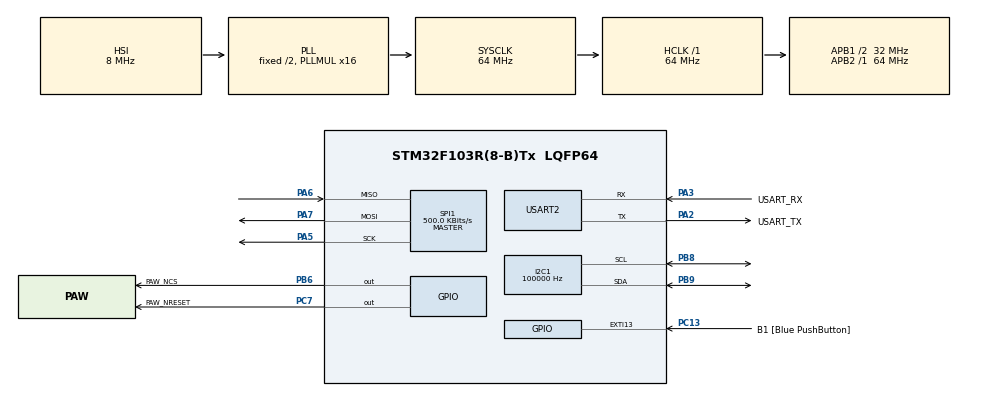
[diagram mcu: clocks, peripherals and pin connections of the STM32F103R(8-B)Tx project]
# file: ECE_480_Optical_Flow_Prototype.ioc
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Mcu.Family=STM32F1
Mcu.Name=STM32F103R(8-B)Tx
Mcu.Package=LQFP64
NVIC.EXTI15_10_IRQn=true\:0\:0\:false\:false\:true\:true\:true\:true
NVIC.PriorityGroup=NVIC_PRIORITYGROUP_4
NVIC.USART2_IRQn=true\:1\:0\:false\:false\:true\:true\:true\:true
PA13.GPIO_Label=TMS
PA13.Mode=Serial_Wire
PA13.Signal=SYS_JTMS-SWDIO
PA14.GPIO_Label=TCK
PA14.Mode=Serial_Wire
PA14.Signal=SYS_JTCK-SWCLK
PA2.GPIO_Label=USART_TX
PA2.GPIO_Mode=GPIO_MODE_AF_PP
PA2.GPIO_PuPd=GPIO_NOPULL
PA2.GPIO_Speed=GPIO_SPEED_FREQ_LOW
PA2.Mode=Asynchronous
PA2.Signal=USART2_TX
PA3.GPIO_Label=USART_RX
PA3.GPIO_Mode=GPIO_MODE_INPUT
PA3.GPIO_PuPd=GPIO_NOPULL
PA3.GPIO_Speed=GPIO_SPEED_FREQ_LOW
PA3.Mode=Asynchronous
PA3.Signal=USART2_RX
PA5.Mode=Full_Duplex_Master
PA5.Signal=SPI1_SCK
PB3.GPIO_Label=SWO
PB3.Signal=SYS_JTDO-TRACESWO
PC13-TAMPER-RTC.GPIO_Label=B1 [Blue PushButton]
PC13-TAMPER-RTC.GPIO_PuPd=GPIO_NOPULL
PC13-TAMPER-RTC.Signal=GPXTI13
PC14-OSC32_IN.Mode=LSE-External-Oscillator
PC14-OSC32_IN.Signal=RCC_OSC32_IN
PC15-OSC32_OUT.Mode=LSE-External-Oscillator
PC15-OSC32_OUT.Signal=RCC_OSC32_OUT
PD0-OSC_IN.Mode=HSE-External-Clock-Source
PD0-OSC_IN.Signal=RCC_OSC_IN
PD1-OSC_OUT.Mode=HSE-External-Clock-Source
PD1-OSC_OUT.Signal=RCC_OSC_OUT
ProjectManager.HeapSize=0x200
ProjectManager.StackSize=0x400
ProjectManager.TargetToolchain=CMake
RCC.AHBFreq_Value=64000000
RCC.APB1CLKDivider=RCC_HCLK_DIV2
RCC.APB1Freq_Value=32000000
RCC.APB1TimFreq_Value=64000000
RCC.APB2Freq_Value=64000000
RCC.APB2TimFreq_Value=64000000
RCC.HCLKFreq_Value=64000000
RCC.PLLMUL=RCC_PLL_MUL16
RCC.RTCClockSelection=RCC_RTCCLKSOURCE_LSE
RCC.SYSCLKFreq_VALUE=64000000
RCC.SYSCLKSource=RCC_SYSCLKSOURCE_PLLCLK
RCC.USBFreq_Value=64000000
USART2.VirtualMode=VM_ASYNC
board=NUCLEO-F103RB
I2C1.ClockSpeed=100000
I2C1.I2C_Speed_Mode=I2C_Standard
NVIC.I2C1_EV_IRQn=true\:2\:0\:false\:false\:true\:true\:true\:true
NVIC.I2C1_ER_IRQn=true\:2\:0\:false\:false\:true\:true\:true\:true
PB8.Mode=I2C
PB8.Signal=I2C1_SCL
PB9.Mode=I2C
PB9.Signal=I2C1_SDA
PA6.Mode=Full_Duplex_Master
PA6.Signal=SPI1_MISO
PA7.Mode=Full_Duplex_Master
PA7.Signal=SPI1_MOSI
PB6.GPIO_Label=PAW_NCS
PB6.GPIO_PuPd=GPIO_PULLUP
PB6.PinState=GPIO_PIN_SET
PB6.Signal=GPIO_Output
PC7.GPIO_Label=PAW_NRESET
PC7.GPIO_PuPd=GPIO_PULLUP
PC7.PinState=GPIO_PIN_SET
PC7.Signal=GPIO_Output
SPI1.BaudRatePrescaler=SPI_BAUDRATEPRESCALER_128
SPI1.CLKPhase=SPI_PHASE_2EDGE
SPI1.CLKPolarity=SPI_POLARITY_HIGH
SPI1.CalculateBaudRate=500.0 KBits/s
SPI1.Direction=SPI_DIRECTION_2LINES
SPI1.Mode=SPI_MODE_MASTER
SPI1.VirtualType=VM_MASTER

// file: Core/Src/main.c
/* USER CODE BEGIN Header */
/**
  ******************************************************************************
  * @file           : main.c
  * @brief          : NUCLEO-F103RB IMU and optical-flow bring-up
  ******************************************************************************
  * @attention
  *
  * Copyright (c) 2026 STMicroelectronics.
  * All rights reserved.
  *
  * This software is licensed under terms that can be found in the LICENSE file
  * in the root directory of this software component.
  * If no LICENSE file comes with this software, it is provided AS-IS.
  *
  ******************************************************************************
  */
/* USER CODE END Header */

#include "main.h"

/* USER CODE BEGIN Includes */
#include "App.h"
/* USER CODE END Includes */

UART_HandleTypeDef huart2;
I2C_HandleTypeDef hi2c1;
SPI_HandleTypeDef hspi1;

void SystemClock_Config(void);
static void MX_GPIO_Init(void);
static void MX_USART2_UART_Init(void);
static void MX_I2C1_Init(void);
static void MX_SPI1_Init(void);

int main(void)
{

  HAL_Init();

  SystemClock_Config();

  MX_GPIO_Init();
  MX_I2C1_Init();
  MX_SPI1_Init();
  MX_USART2_UART_Init();

  /* USER CODE BEGIN 2 */
  App_Init();
  /* USER CODE END 2 */

  while (1)
  {

    /* USER CODE BEGIN 3 */
    App_Task();
  }
  /* USER CODE END 3 */
}

void SystemClock_Config(void)
{
  RCC_OscInitTypeDef RCC_OscInitStruct = {0};
  RCC_ClkInitTypeDef RCC_ClkInitStruct = {0};

  RCC_OscInitStruct.OscillatorType = RCC_OSCILLATORTYPE_HSI;
  RCC_OscInitStruct.HSIState = RCC_HSI_ON;
  RCC_OscInitStruct.HSICalibrationValue = RCC_HSICALIBRATION_DEFAULT;
  RCC_OscInitStruct.PLL.PLLState = RCC_PLL_ON;
  RCC_OscInitStruct.PLL.PLLSource = RCC_PLLSOURCE_HSI_DIV2;
  RCC_OscInitStruct.PLL.PLLMUL = RCC_PLL_MUL16;
  if (HAL_RCC_OscConfig(&RCC_OscInitStruct) != HAL_OK)
  {
    Error_Handler();
  }

  RCC_ClkInitStruct.ClockType = RCC_CLOCKTYPE_HCLK | RCC_CLOCKTYPE_SYSCLK
                              | RCC_CLOCKTYPE_PCLK1 | RCC_CLOCKTYPE_PCLK2;
  RCC_ClkInitStruct.SYSCLKSource = RCC_SYSCLKSOURCE_PLLCLK;
  RCC_ClkInitStruct.AHBCLKDivider = RCC_SYSCLK_DIV1;
  RCC_ClkInitStruct.APB1CLKDivider = RCC_HCLK_DIV2;
  RCC_ClkInitStruct.APB2CLKDivider = RCC_HCLK_DIV1;

  if (HAL_RCC_ClockConfig(&RCC_ClkInitStruct, FLASH_LATENCY_2) != HAL_OK)
  {
    Error_Handler();
  }
}

static void MX_I2C1_Init(void)
{
  hi2c1.Instance = I2C1;
  hi2c1.Init.ClockSpeed = 100000;
  hi2c1.Init.DutyCycle = I2C_DUTYCYCLE_2;
  hi2c1.Init.OwnAddress1 = 0;
  hi2c1.Init.AddressingMode = I2C_ADDRESSINGMODE_7BIT;
  hi2c1.Init.DualAddressMode = I2C_DUALADDRESS_DISABLE;
  hi2c1.Init.OwnAddress2 = 0;
  hi2c1.Init.GeneralCallMode = I2C_GENERALCALL_DISABLE;
  hi2c1.Init.NoStretchMode = I2C_NOSTRETCH_DISABLE;
  if (HAL_I2C_Init(&hi2c1) != HAL_OK)
  {
    Error_Handler();
  }
}

static void MX_SPI1_Init(void)
{
  hspi1.Instance = SPI1;
  hspi1.Init.Mode = SPI_MODE_MASTER;
  hspi1.Init.Direction = SPI_DIRECTION_2LINES;
  hspi1.Init.DataSize = SPI_DATASIZE_8BIT;
  hspi1.Init.CLKPolarity = SPI_POLARITY_HIGH;
  hspi1.Init.CLKPhase = SPI_PHASE_2EDGE;
  hspi1.Init.NSS = SPI_NSS_SOFT;
  /* APB2 is 64 MHz: /128 gives a conservative 500 kHz serial clock. */
  hspi1.Init.BaudRatePrescaler = SPI_BAUDRATEPRESCALER_128;
  hspi1.Init.FirstBit = SPI_FIRSTBIT_MSB;
  hspi1.Init.TIMode = SPI_TIMODE_DISABLE;
  hspi1.Init.CRCCalculation = SPI_CRCCALCULATION_DISABLE;
  hspi1.Init.CRCPolynomial = 7;
  if (HAL_SPI_Init(&hspi1) != HAL_OK)
  {
    Error_Handler();
  }
}

static void MX_USART2_UART_Init(void)
{

  huart2.Instance = USART2;
  huart2.Init.BaudRate = 115200;
  huart2.Init.WordLength = UART_WORDLENGTH_8B;
  huart2.Init.StopBits = UART_STOPBITS_1;
  huart2.Init.Parity = UART_PARITY_NONE;
  huart2.Init.Mode = UART_MODE_TX_RX;
  huart2.Init.HwFlowCtl = UART_HWCONTROL_NONE;
  huart2.Init.OverSampling = UART_OVERSAMPLING_16;
  if (HAL_UART_Init(&huart2) != HAL_OK)
  {
    Error_Handler();
  }

}

static void MX_GPIO_Init(void)
{
  GPIO_InitTypeDef GPIO_InitStruct = {0};

  __HAL_RCC_GPIOC_CLK_ENABLE();
  __HAL_RCC_GPIOD_CLK_ENABLE();
  __HAL_RCC_GPIOA_CLK_ENABLE();
  __HAL_RCC_GPIOB_CLK_ENABLE();

  /* PA5 is SPI1 SCLK; it is no longer an independently controlled LED pin. */
  HAL_GPIO_WritePin(PAW_NCS_GPIO_Port, PAW_NCS_Pin, GPIO_PIN_SET);
  HAL_GPIO_WritePin(PAW_NRESET_GPIO_Port, PAW_NRESET_Pin, GPIO_PIN_SET);

  GPIO_InitStruct.Pin = B1_Pin;
  GPIO_InitStruct.Mode = GPIO_MODE_IT_RISING;
  GPIO_InitStruct.Pull = GPIO_NOPULL;
  HAL_GPIO_Init(B1_GPIO_Port, &GPIO_InitStruct);

  GPIO_InitStruct.Pin = PAW_NCS_Pin;
  GPIO_InitStruct.Mode = GPIO_MODE_OUTPUT_PP;
  GPIO_InitStruct.Pull = GPIO_PULLUP;
  GPIO_InitStruct.Speed = GPIO_SPEED_FREQ_LOW;
  HAL_GPIO_Init(PAW_NCS_GPIO_Port, &GPIO_InitStruct);

  GPIO_InitStruct.Pin = PAW_NRESET_Pin;
  HAL_GPIO_Init(PAW_NRESET_GPIO_Port, &GPIO_InitStruct);

  HAL_NVIC_SetPriority(EXTI15_10_IRQn, 0, 0);
  HAL_NVIC_EnableIRQ(EXTI15_10_IRQn);

}

void Error_Handler(void)
{
  __disable_irq();
  while (1)
  {
  }
}

#ifdef USE_FULL_ASSERT
void assert_failed(uint8_t *file, uint32_t line)
{
  /* USER CODE BEGIN 6 */
  (void)file;
  (void)line;
  /* USER CODE END 6 */
}
#endif
